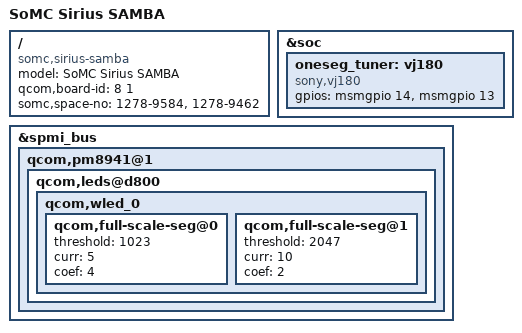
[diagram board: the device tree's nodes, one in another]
/* arch/arm/boot/dts/qcom/msm8974pro-ab-shinano_sirius_samba.dts
 *
 * Copyright (c) 2013-2014, The Linux Foundation. All rights reserved.
 * Copyright (C) 2013 Sony Mobile Communications Inc.
 *
 * Author: Shougo Watanabe <Shougo.X.Watanabe@sonymobile.com>
 *
 * This program is free software; you can redistribute it and/or modify
 * it under the terms of the GNU General Public License version 2 and
 * only version 2 as published by the Free Software Foundation.
 *
 * This program is distributed in the hope that it will be useful,
 * but WITHOUT ANY WARRANTY; without even the implied warranty of
 * MERCHANTABILITY or FITNESS FOR A PARTICULAR PURPOSE.  See the
 * GNU General Public License for more details.
 */

/dts-v1/;

#include "msm8974pro-ab-pm8941.dtsi"
#include "msm8974-mtp.dtsi"
#include "msm8974pro-ab-shinano_common.dtsi"
#include "msm8974pro-ab-shinano_sirius.dtsi"
#include "msm8974pro-ab-camera-sensor-sirius.dtsi"
#include "dsi-panel-sirius.dtsi"

/ {
	model = "SoMC Sirius SAMBA";
	compatible = "somc,sirius-samba", "qcom,msm8974";
        qcom,board-id = <8 1>;
	somc,space-no = "1278-9584",
			"1278-9462";
};


&soc {
	oneseg_tuner: vj180 {
		compatible = "sony,vj180";
		gpios = <&msmgpio 14 0>, /* TUNER_POWER */
			<&msmgpio 13 0>; /* TUNER_RESET */
	};
};

&spmi_bus {
	qcom,pm8941@1 {
		qcom,leds@d800 {
			qcom,wled_0 {
				qcom,full-scale-seg@0 {
					threshold = <1023>;
					curr = <5>;
					coef = <4>;
				};
				qcom,full-scale-seg@1 {
					threshold = <2047>;
					curr = <10>;
					coef = <2>;
				};
			};
		};
	};
};
